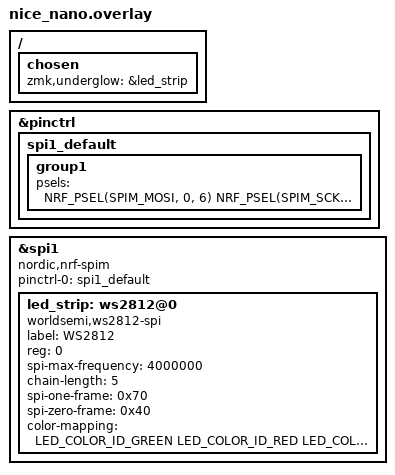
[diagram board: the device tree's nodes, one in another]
/* Copyright (c) 2021-2022 The ZMK Contributors
 * SPDX-License-Identifier: MIT
 */

#include <dt-bindings/led/led.h>
#include <dt-bindings/pinctrl/nrf-pinctrl.h>

/ {
    chosen {
        zmk,underglow = &led_strip;
    };
};

&pinctrl {
    spi1_default: spi1_default {
        group1 {
            psels = <
                NRF_PSEL(SPIM_MOSI, 0, 6)
                NRF_PSEL(SPIM_SCK,  0, 5)
                NRF_PSEL(SPIM_MISO, 0, 7)
            >;
        };
    };
};

&spi1 {
    compatible = "nordic,nrf-spim";
    status = "okay";

    pinctrl-0 = <&spi1_default>;
    pinctrl-names = "default";

    led_strip: ws2812@0 {
        compatible = "worldsemi,ws2812-spi";
        label = "WS2812";

        reg = <0>;
        spi-max-frequency = <4000000>;

        chain-length = <5>;
        spi-one-frame = <0x70>;
        spi-zero-frame = <0x40>;

        color-mapping = <
            LED_COLOR_ID_GREEN
            LED_COLOR_ID_RED
            LED_COLOR_ID_BLUE
        >;
    };
};
